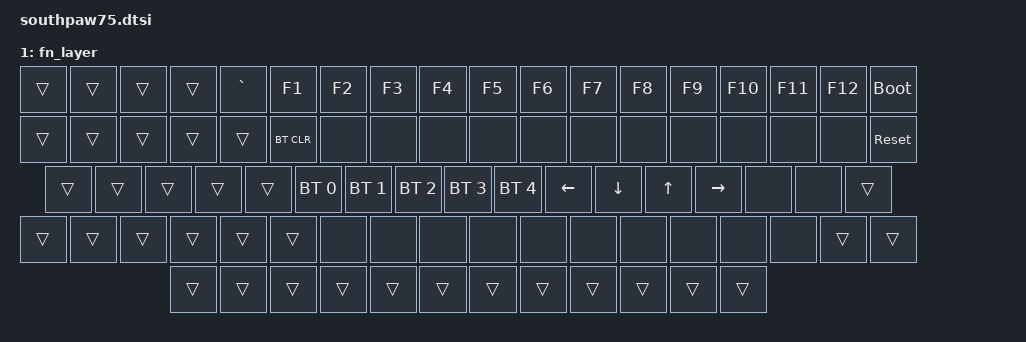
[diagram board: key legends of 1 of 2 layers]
/*
 * Copyright (c) 2020 The ZMK Contributors
 *
 * SPDX-License-Identifier: MIT
 */

#include <behaviors.dtsi>
#include <dt-bindings/zmk/keys.h>
#include <dt-bindings/zmk/bt.h>
#include <dt-bindings/zmk/rgb.h>
/* 1. ADDED PHYSICAL LAYOUT HEADER */
#include <dt-bindings/zmk/physical-layout.h> 

/ {
    chosen {
        zmk,kscan = &kscan0;
        zmk,matrix_transform = &default_transform;
        /* 2. ADDED LAYOUT POINTER TO CHOSEN NODE */
        zmk,physical-layout = &physical_layout0; 
    };

    default_transform: keymap_transform_0 {
        compatible = "zmk,matrix-transform";
        columns = <9>;
        rows = <9>;

        map = <
RC(0,0) RC(0,1) RC(0,2) RC(0,3)    RC(0,4) RC(0,5) RC(0,6) RC(0,7) RC(0,8) RC(1,0) RC(1,1) RC(1,2) RC(1,3) RC(1,4) RC(1,5) RC(1,6) RC(1,7) RC(1,8)
RC(2,0) RC(2,1) RC(2,2) RC(2,3)    RC(2,4) RC(2,5) RC(2,6) RC(2,7) RC(2,8) RC(3,0) RC(3,1) RC(3,2) RC(3,3) RC(3,4) RC(3,5) RC(3,6) RC(3,7) RC(3,8)
RC(4,0) RC(4,1) RC(4,2)            RC(4,3) RC(4,4) RC(4,5) RC(4,6) RC(4,7) RC(4,8) RC(5,0) RC(5,1) RC(5,2) RC(5,3) RC(5,4) RC(5,5) RC(5,6)
RC(5,7) RC(5,8) RC(6,0) RC(6,1)    RC(6,2) RC(6,3) RC(6,4) RC(6,5) RC(6,6) RC(6,7) RC(6,8) RC(7,0) RC(7,1) RC(7,2) RC(7,3) RC(7,4) RC(7,5) RC(8,7)
   RC(7,6)      RC(7,7)            RC(7,8) RC(8,0) RC(8,1)                         RC(8,2)                         RC(8,3) RC(8,4) RC(8,5) RC(8,6)
        >;
    };

    /* 3. ADDED THE FULL PHYSICAL LAYOUT NODE */
    physical_layout0: physical_layout_0 {
        compatible = "zmk,physical-layout";
        display-name = "SP75 Default Layout";
        kscan = <&kscan0>;
        transform = <&default_transform>;

        /* * 1U (Standard Alpha Key) = 100 width, 100 height.
         * Format: <&key_physical_attrs width height X Y rotation rx ry>
         */
        keys = <
            /* ROW 0: Y = 0 */
            /* NUMPAD LEFT (4 Keys) */
            &key_physical_attrs 100 100 0    0 0 0 0  /* NUM */
            &key_physical_attrs 100 100 100  0 0 0 0  /* / */
            &key_physical_attrs 100 100 200  0 0 0 0  /* * */
            &key_physical_attrs 100 100 300  0 0 0 0  /* - */
            /* MAIN BOARD (Assumes 0.5U / 50pt gap between numpad and main board) */
            &key_physical_attrs 100 100 450  0 0 0 0  /* ESC */
            &key_physical_attrs 100 100 550  0 0 0 0  /* 1 */
            &key_physical_attrs 100 100 650  0 0 0 0  /* 2 */
            &key_physical_attrs 100 100 750  0 0 0 0  /* 3 */
            &key_physical_attrs 100 100 850  0 0 0 0  /* 4 */
            &key_physical_attrs 100 100 950  0 0 0 0  /* 5 */
            &key_physical_attrs 100 100 1050 0 0 0 0  /* 6 */
            &key_physical_attrs 100 100 1150 0 0 0 0  /* 7 */
            &key_physical_attrs 100 100 1250 0 0 0 0  /* 8 */
            &key_physical_attrs 100 100 1350 0 0 0 0  /* 9 */
            &key_physical_attrs 100 100 1450 0 0 0 0  /* 0 */
            &key_physical_attrs 100 100 1550 0 0 0 0  /* - */
            &key_physical_attrs 100 100 1650 0 0 0 0  /* = */
            &key_physical_attrs 200 100 1750 0 0 0 0  /* BACKSPACE (2U wide = 200) */

            /* ROW 1: Y = 100 */
            &key_physical_attrs 100 100 0    100 0 0 0  /* 7 */
            &key_physical_attrs 100 100 100  100 0 0 0  /* 8 */
            &key_physical_attrs 100 100 200  100 0 0 0  /* 9 */
            &key_physical_attrs 100 100 300  100 0 0 0  /* GHOST */
            /* MAIN BOARD (Tab is 1.5U wide) */
            &key_physical_attrs 150 100 450  100 0 0 0  /* TAB */
            &key_physical_attrs 100 100 600  100 0 0 0  /* Q */
            &key_physical_attrs 100 100 700  100 0 0 0  /* W */
            &key_physical_attrs 100 100 800  100 0 0 0  /* E */
            &key_physical_attrs 100 100 900  100 0 0 0  /* R */
            &key_physical_attrs 100 100 1000 100 0 0 0  /* T */
            &key_physical_attrs 100 100 1100 100 0 0 0  /* Y */
            &key_physical_attrs 100 100 1200 100 0 0 0  /* U */
            &key_physical_attrs 100 100 1300 100 0 0 0  /* I */
            &key_physical_attrs 100 100 1400 100 0 0 0  /* O */
            &key_physical_attrs 100 100 1500 100 0 0 0  /* P */
            &key_physical_attrs 100 100 1600 100 0 0 0  /* [ */
            &key_physical_attrs 100 100 1700 100 0 0 0  /* ] */
            &key_physical_attrs 150 100 1800 100 0 0 0  /* \ (1.5U wide) */

            /* ROW 2: Y = 200 */
            /* YOU NEED TO MAP THIS ROW */
            /* Hint: CAPS is usually 1.75U (175 width), ENTER is usually 2.25U (225 width) */
            &key_physical_attrs 100 100 0 200 0 0 0 /* 4 */
            /* ... map the rest of the 17 keys in this row ... */

            /* ROW 3: Y = 300 */
            /* YOU NEED TO MAP THIS ROW */
            /* Hint: LSHFT is usually 2.25U, RSHFT is usually 1.75U + 1U for MO(2) depending on your arrow cluster */
            &key_physical_attrs 100 100 0 300 0 0 0 /* 1 */
            /* ... map the rest of the 18 keys in this row ... */

            /* ROW 4: Y = 400 */
            /* YOU NEED TO MAP THIS ROW */
            /* Hint: Numpad 0 is 200 width. Spacebar is likely 625 width (6.25U) */
            &key_physical_attrs 200 100 0 400 0 0 0 /* 0 */
            /* ... map the rest of the 10 keys in this row ... */
        >;
    };

    kscan0: kscan_0 {
        compatible = "zmk,kscan-gpio-matrix";
        wakeup-source;

        diode-direction = "col2row";

        col-gpios
            = <&pro_micro  9 GPIO_ACTIVE_HIGH>
            , <&pro_micro 21 GPIO_ACTIVE_HIGH>
            , <&pro_micro 20 GPIO_ACTIVE_HIGH>
            , <&pro_micro 19 GPIO_ACTIVE_HIGH>
            , <&pro_micro 18 GPIO_ACTIVE_HIGH>
            , <&pro_micro 15 GPIO_ACTIVE_HIGH>
            , <&pro_micro 14 GPIO_ACTIVE_HIGH>
            , <&pro_micro 16 GPIO_ACTIVE_HIGH>
            , <&pro_micro 10 GPIO_ACTIVE_HIGH>
            ;

        row-gpios
            = <&pro_micro 1 (GPIO_ACTIVE_HIGH | GPIO_PULL_DOWN)>
            , <&pro_micro 0 (GPIO_ACTIVE_HIGH | GPIO_PULL_DOWN)>
            , <&pro_micro 2 (GPIO_ACTIVE_HIGH | GPIO_PULL_DOWN)>
            , <&pro_micro 3 (GPIO_ACTIVE_HIGH | GPIO_PULL_DOWN)>
            , <&pro_micro 4 (GPIO_ACTIVE_HIGH | GPIO_PULL_DOWN)>
            , <&pro_micro 5 (GPIO_ACTIVE_HIGH | GPIO_PULL_DOWN)>
            , <&pro_micro 6 (GPIO_ACTIVE_HIGH | GPIO_PULL_DOWN)>
            , <&pro_micro 7 (GPIO_ACTIVE_HIGH | GPIO_PULL_DOWN)>
            , <&pro_micro 8 (GPIO_ACTIVE_HIGH | GPIO_PULL_DOWN)>
            ;
    };

    keymap0: keymap {
        compatible = "zmk,keymap";

        default_layer {
// ------------------------------------------------------------------------------------------------------------------
// | NUM |  /  |  * |  -  | ESC |  1  |  2  |  3  |  4  |  5  |  6  |  7  |  8  |  9  |  0  |  -  |  =  |   BKSP   |
// |  7  |  8  |  9  | GHOST| TAB |  Q  |  W  |  E  |  R  |  T  |  Y  |  U  |  I  |  O  |  P  |  [  |  ]  |    \    |
// |  4  |  5  |  6  | ENT | CAPS  |  A  |  S  |  D  |  F  |  G  |  H  |  J  |  K  |  L  |  ;  |  '  |     ENTER    |
// |  1  |  2  |  3  |     |  SHIFT  |GHOST|  Z  |  X  |  C  |  V  |  B  |  N  |  M  |  ,  |  .  |  /  |  SHIFT   | MO(2) |
// |     0     |  .  |     |  CTL  |  WIN  |  ALT  |              SPACE              |  ALT  | MO(1) |  WIN  | CTRL  |
// ------------------------------------------------------------------------------------------------------------------
            bindings = <
                &kp KP_NLCK &kp KP_DIVIDE &kp KP_MULTIPLY &kp KP_MINUS   &kp ESC         &kp N1 &kp N2 &kp N3 &kp N4 &kp N5 &kp N6 &kp N7 &kp   N8  &kp  N9 &kp  N0  &kp MINUS &kp EQUAL &kp BSPC
                &kp N7      &kp N8        &kp N9          &none          &kp TAB         &kp Q  &kp W  &kp E  &kp R  &kp T  &kp Y  &kp U  &kp   I   &kp  O  &kp   P  &kp LBKT &kp RBKT  &kp BSLH
                &kp N4      &kp N5        &kp N6                                 &kp CLCK          &kp A  &kp S  &kp D  &kp F  &kp G  &kp H  &kp J  &kp   K   &kp  L  &kp SEMI &kp SQT            &kp RET
                &kp N1      &kp N2        &kp N3          &kp KP_ENTER   &kp LSHFT &none    &kp Z  &kp X  &kp C  &kp V  &kp B  &kp N  &kp M  &kp COMMA &kp DOT &kp FSLH        &kp RSHFT &mo  2
                    &kp N0              &kp DOT                        &kp LCTRL &kp LGUI &kp LALT               &kp SPACE                 &kp  RALT  &mo  1  &kp  RGUI  &kp  RCTRL
            >;
        };

        fn_layer {
            bindings = <
                &trans      &trans        &trans          &trans         &kp GRAVE  &kp F1     &kp F2     &kp F3     &kp F4     &kp F5     &kp F6     &kp F7     &kp F8     &kp F9     &kp F10    &kp F11    &kp F12    &bootloader
                &trans      &trans        &trans          &trans         &trans         &bt BT_CLR &none      &none      &none      &none      &none      &none      &none      &none      &none      &none      &none      &sys_reset
                &trans      &trans        &trans          &trans         &trans           &bt BT_SEL 0 &bt BT_SEL 1 &bt BT_SEL 2 &bt BT_SEL 3 &bt BT_SEL 4 &kp LEFT   &kp DOWN   &kp UP   &kp RIGHT   &none      &none      &trans
                &trans      &trans        &trans          &trans         &trans &trans         &none      &none      &none      &none      &none      &none      &none      &none      &none      &none          &trans     &trans
                &trans      &trans        &trans          &trans         &trans       &trans       &trans                                            &trans                                            &trans     &trans     &trans     &trans
            >;
        };
    };
};
